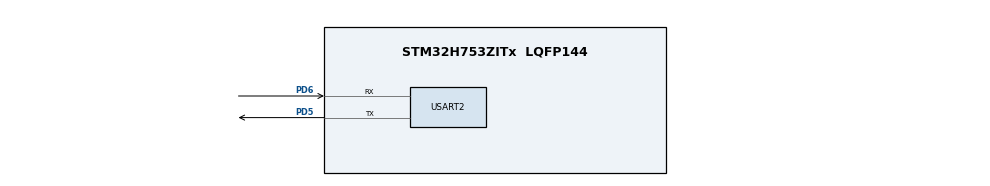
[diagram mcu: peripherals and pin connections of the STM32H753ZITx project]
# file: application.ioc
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CORTEX_M7.default_mode_Activation=1
Mcu.Family=STM32H7
Mcu.Name=STM32H753ZITx
Mcu.Package=LQFP144
NVIC.PriorityGroup=NVIC_PRIORITYGROUP_4
PD5.Mode=Asynchronous
PD5.Signal=USART2_TX
PD6.Mode=Asynchronous
PD6.Signal=USART2_RX
ProjectManager.HeapSize=0x200
ProjectManager.StackSize=0x400
ProjectManager.TargetToolchain=STM32CubeIDE
RCC.ADCFreq_Value=129000000
RCC.APB1Freq_Value=32000000
RCC.APB2Freq_Value=64000000
RCC.APB3Freq_Value=64000000
RCC.APB4Freq_Value=64000000
RCC.CortexFreq_Value=64000000
RCC.D2PPRE1=RCC_APB1_DIV2
RCC.HCLKFreq_Value=64000000
RCC.SYSCLKFreq_VALUE=64000000
RCC.USBFreq_Value=129000000
USART2.VirtualMode-Asynchronous=VM_ASYNC
VP_MEMORYMAP_VS_MEMORYMAP.Mode=CurAppReg
board=custom

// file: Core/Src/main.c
/* USER CODE BEGIN Header */
/**
  ******************************************************************************
  * @file           : main.c
  * @brief          : Main program body
  ******************************************************************************
  * @attention
  *
  * Copyright (c) 2026 STMicroelectronics.
  * All rights reserved.
  *
  * This software is licensed under terms that can be found in the LICENSE file
  * in the root directory of this software component.
  * If no LICENSE file comes with this software, it is provided AS-IS.
  *
  ******************************************************************************
  */
/* USER CODE END Header */
#include "main.h"

UART_HandleTypeDef huart2;

void SystemClock_Config(void);
static void MPU_Config(void);
static void MX_GPIO_Init(void);
static void MX_USART2_UART_Init(void);

int main(void)
{

  /* MPU Configuration--------------------------------------------------------*/
  MPU_Config();

  /* MCU Configuration--------------------------------------------------------*/

  /* Reset of all peripherals, Initializes the Flash interface and the Systick. */
  HAL_Init();

  /* Configure the system clock */
  SystemClock_Config();

  /* Initialize all configured peripherals */
  MX_GPIO_Init();
  MX_USART2_UART_Init();

  /* Infinite loop */
  /* USER CODE BEGIN WHILE */
  char msg[] = "Hello from STM32 UART!\r\n";
  while (1)
  {
    HAL_Delay(2000);
    HAL_UART_Transmit(&huart2, (uint8_t*)msg, sizeof(msg) - 1, HAL_MAX_DELAY);
    /* USER CODE END WHILE */

  }
}

void SystemClock_Config(void)
{
  RCC_OscInitTypeDef RCC_OscInitStruct = {0};
  RCC_ClkInitTypeDef RCC_ClkInitStruct = {0};

  /** Supply configuration update enable
  */
  HAL_PWREx_ConfigSupply(PWR_LDO_SUPPLY);

  /** Configure the main internal regulator output voltage
  */
  __HAL_PWR_VOLTAGESCALING_CONFIG(PWR_REGULATOR_VOLTAGE_SCALE3);

  while(!__HAL_PWR_GET_FLAG(PWR_FLAG_VOSRDY)) {}

  /** Initializes the RCC Oscillators according to the specified parameters
  * in the RCC_OscInitTypeDef structure.
  */
  RCC_OscInitStruct.OscillatorType = RCC_OSCILLATORTYPE_HSI;
  RCC_OscInitStruct.HSIState = RCC_HSI_DIV1;
  RCC_OscInitStruct.HSICalibrationValue = RCC_HSICALIBRATION_DEFAULT;
  RCC_OscInitStruct.PLL.PLLState = RCC_PLL_NONE;
  if (HAL_RCC_OscConfig(&RCC_OscInitStruct) != HAL_OK)
  {
    Error_Handler();
  }

  /** Initializes the CPU, AHB and APB buses clocks
  */
  RCC_ClkInitStruct.ClockType = RCC_CLOCKTYPE_HCLK|RCC_CLOCKTYPE_SYSCLK
                              |RCC_CLOCKTYPE_PCLK1|RCC_CLOCKTYPE_PCLK2
                              |RCC_CLOCKTYPE_D3PCLK1|RCC_CLOCKTYPE_D1PCLK1;
  RCC_ClkInitStruct.SYSCLKSource = RCC_SYSCLKSOURCE_HSI;
  RCC_ClkInitStruct.SYSCLKDivider = RCC_SYSCLK_DIV1;
  RCC_ClkInitStruct.AHBCLKDivider = RCC_HCLK_DIV1;
  RCC_ClkInitStruct.APB3CLKDivider = RCC_APB3_DIV1;
  RCC_ClkInitStruct.APB1CLKDivider = RCC_APB1_DIV2;
  RCC_ClkInitStruct.APB2CLKDivider = RCC_APB2_DIV1;
  RCC_ClkInitStruct.APB4CLKDivider = RCC_APB4_DIV1;

  if (HAL_RCC_ClockConfig(&RCC_ClkInitStruct, FLASH_LATENCY_1) != HAL_OK)
  {
    Error_Handler();
  }
}

static void MX_USART2_UART_Init(void)
{

  huart2.Instance = USART2;
  huart2.Init.BaudRate = 115200;
  huart2.Init.WordLength = UART_WORDLENGTH_8B;
  huart2.Init.StopBits = UART_STOPBITS_1;
  huart2.Init.Parity = UART_PARITY_NONE;
  huart2.Init.Mode = UART_MODE_TX_RX;
  huart2.Init.HwFlowCtl = UART_HWCONTROL_NONE;
  huart2.Init.OverSampling = UART_OVERSAMPLING_16;
  huart2.Init.OneBitSampling = UART_ONE_BIT_SAMPLE_DISABLE;
  huart2.Init.ClockPrescaler = UART_PRESCALER_DIV1;
  huart2.AdvancedInit.AdvFeatureInit = UART_ADVFEATURE_NO_INIT;
  if (HAL_UART_Init(&huart2) != HAL_OK)
  {
    Error_Handler();
  }
  if (HAL_UARTEx_SetTxFifoThreshold(&huart2, UART_TXFIFO_THRESHOLD_1_8) != HAL_OK)
  {
    Error_Handler();
  }
  if (HAL_UARTEx_SetRxFifoThreshold(&huart2, UART_RXFIFO_THRESHOLD_1_8) != HAL_OK)
  {
    Error_Handler();
  }
  if (HAL_UARTEx_DisableFifoMode(&huart2) != HAL_OK)
  {
    Error_Handler();
  }

}

static void MX_GPIO_Init(void)
{

  /* GPIO Ports Clock Enable */
  __HAL_RCC_GPIOD_CLK_ENABLE();

}

 /* MPU Configuration */

void MPU_Config(void)
{
  MPU_Region_InitTypeDef MPU_InitStruct = {0};

  /* Disables the MPU */
  HAL_MPU_Disable();

  /** Initializes and configures the Region and the memory to be protected
  */
  MPU_InitStruct.Enable = MPU_REGION_ENABLE;
  MPU_InitStruct.Number = MPU_REGION_NUMBER0;
  MPU_InitStruct.BaseAddress = 0x0;
  MPU_InitStruct.Size = MPU_REGION_SIZE_4GB;
  MPU_InitStruct.SubRegionDisable = 0x87;
  MPU_InitStruct.TypeExtField = MPU_TEX_LEVEL0;
  MPU_InitStruct.AccessPermission = MPU_REGION_NO_ACCESS;
  MPU_InitStruct.DisableExec = MPU_INSTRUCTION_ACCESS_DISABLE;
  MPU_InitStruct.IsShareable = MPU_ACCESS_SHAREABLE;
  MPU_InitStruct.IsCacheable = MPU_ACCESS_NOT_CACHEABLE;
  MPU_InitStruct.IsBufferable = MPU_ACCESS_NOT_BUFFERABLE;

  HAL_MPU_ConfigRegion(&MPU_InitStruct);
  /* Enables the MPU */
  HAL_MPU_Enable(MPU_PRIVILEGED_DEFAULT);

}

void Error_Handler(void)
{
  __disable_irq();
  while (1)
  {
  }
}
